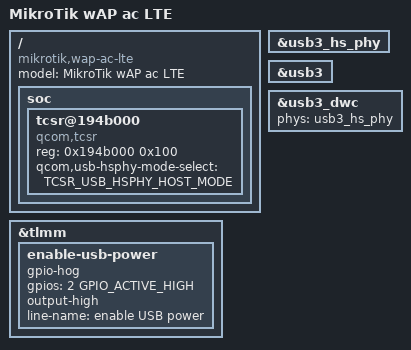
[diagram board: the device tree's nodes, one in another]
// SPDX-License-Identifier: GPL-2.0-or-later OR MIT
/* Copyright (c) 2022, Alexander Couzens <lynxis@fe80.eu> */

#include "qcom-ipq4018-wap-ac.dtsi"

/ {
	model = "MikroTik wAP ac LTE";
	compatible = "mikrotik,wap-ac-lte";

	soc {
		tcsr@194b000 {
			/* select hostmode */
			compatible = "qcom,tcsr";
			reg = <0x194b000 0x100>;
			qcom,usb-hsphy-mode-select = <TCSR_USB_HSPHY_HOST_MODE>;
			status = "okay";
		};
	};
};

&tlmm {
	enable-usb-power {
		gpio-hog;
		gpios = <2 GPIO_ACTIVE_HIGH>;
		output-high;
		line-name = "enable USB power";
	};
};

&usb3_hs_phy {
	status = "okay";
};

&usb3 {
	status = "okay";
};

&usb3_dwc {
	phys = <&usb3_hs_phy>;
	phy-names = "usb2-phy";
};
